# MEC1701Q register map
Vendor: Microchip Technology; Series: MEC1701; File version: 0
CPU: CM4 r1p0, little endian, MPU, FPU, 3 interrupt priority bits
Registers are 32-bit, read-write, reset 0x0 unless marked. A register's access mark holds for its fields unless they carry their own. Offsets are from the block's base; [hi:lo] are bit positions; {n}, {i} and the like mark numbered series; 'fields as' and 'values as' point back to an identical list.

## PM1 — The device implements the ACPI fixed registers but includes only those bits that apply to the power button sleep button and RTC alarm events. The ACPI WAK_STS, SLP_TYP and SLP_EN bits are also supported.
Base 0x400F1C00; register names take the prefix PM1_
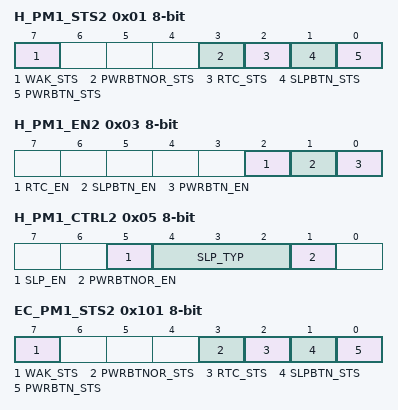
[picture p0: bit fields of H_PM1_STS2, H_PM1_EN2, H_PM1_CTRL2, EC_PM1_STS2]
0x01 H_PM1_STS2 8-bit — PM1 Status 2
  [7] WAK_STS — This bit can be set or cleared by the EC. The Host writing a one to this bit can also clear this bit. (R/WC)
  [3] PWRBTNOR_STS — This bit can be set or cleared by the EC to simulate a Power button override event status if the power is controlled by the EC. The Host writing a one to this bit can also clear this bit. The EC must generate the associated hardware event under software control.(R/WC)
  [2] RTC_STS — This bit can be set or cleared by the EC to simulate a RTC status. The Host writing a one to this bit can also clear this bit. The EC must generate the associated SCI interrupt under software control. (R/WC)
  [1] SLPBTN_STS — This bit can be set or cleared by the EC to simulate a Sleep button status if the sleep state is controlled by the EC. The Host writing a one to this bit can also clear this bit. The EC must generate the associated SCI interrupt under software control.(R/WC)
  [0] PWRBTN_STS — This bit can be set or cleared by the EC to simulate a Power button status if the power is controlled by the EC. The Host writing a one to this bit can also clear this bit. The EC must generate the associated SCI interrupt under software control. (R/WC)
0x03 H_PM1_EN2 8-bit — PM1 Enable 2
  [2] RTC_EN — This bit can be read or written by the Host. It can be read by the EC.
  [1] SLPBTN_EN — This bit can be read or written by the Host. It can be read by the EC.
  [0] PWRBTN_EN — This bit can be read or written by the Host. It can be read by the EC.
0x05 H_PM1_CTRL2 8-bit — PM1 Control 2
  [5] SLP_EN
  [4:2] SLP_TYP — These bits can be set or cleared by the Host, read by the EC.
  [1] PWRBTNOR_EN — This bit can be set or cleared by the Host, read by the EC.
0x101 EC_PM1_STS2 8-bit — PM1 Status 2
  fields as H_PM1_STS2
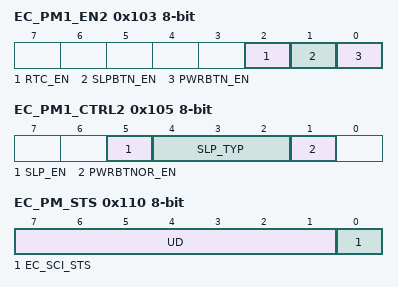
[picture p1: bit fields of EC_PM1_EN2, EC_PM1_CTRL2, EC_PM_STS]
0x103 EC_PM1_EN2 8-bit — PM1 Enable 2
  fields as H_PM1_EN2
0x105 EC_PM1_CTRL2 8-bit — PM1 Control 2
  fields as H_PM1_CTRL2
0x110 EC_PM_STS 8-bit — PM1 EC PM Status
  [7:1] UD — User Defined
  [0] EC_SCI_STS — If the EC_SCI_STS bit is '1', an interrupt is generated on the EC_SCI# pin.

## PS2_0 — There are four PS/2 Ports which are directly controlled by the EC. The hardware implementation eliminates the need to bit bang I/O ports to generate PS/2 traffic, however bit banging is available via the associated GPIO pins.
Base 0x40009000; register names take the prefix PS2_
Same registers: PS2_1 0x40009040, PS2_2 0x40009080
0x00 TX_DATA wo — Writes to bits 7:0 of this register start a transmission of the data in this register to the peripheral
0x00 RX_DATA ro reset 0xFF — Data received from a peripheral are recorded in this register in bits 7:0.
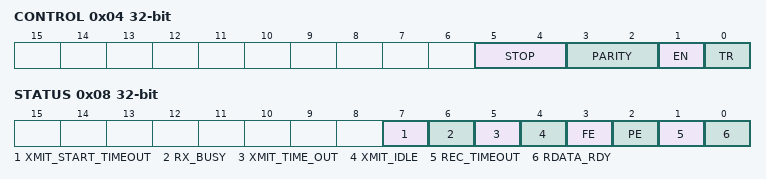
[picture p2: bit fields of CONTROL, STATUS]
0x04 CONTROL — PS2 Control Register
  [5:4] STOP — 00b=Receiver expects an active high stop bit. 01b=Receiver expects an active low stop bit. 10b=Receiver ignores the level of the Stop bit (11th bit is not interpreted as a stop bit). 11b=Reserved.
  [3:2] PARITY — 00b=Receiver expects Odd Parity (default). 01b=Receiver expects Even Parity. 10b=Receiver ignores level of the parity bit (10th bit is not interpreted as a parity bit). 11b=Reserved
  [1] EN — PS/2 Enable. 0=The PS/2 state machine is disabled. 1=The PS/2 state machine is enabled.
  [0] TR — PS/2 Transmit/Receive. 0=The P2/2 channel is enabled to receive data. 1=The PS2 channel is enabled to transmit data.
0x08 STATUS — PS2 Status Register
  [7] XMIT_START_TIMEOUT — Transmit Start Timeout. 0=No transmit start timeout detected. 1=A start bit was not received within 25 ms following the transmit start event. The transmit start bit time-out condition is also indicated by the XMIT_TIMEOUT bit.
  [6] RX_BUSY — Receive Channel Busy. 0=The channel is idle. 1=The channel is actively receiving PS/2 data
  [5] XMIT_TIME_OUT — Transmitter Time-out. When the XMIT_TIMEOUT bit is set, the PS2_T/R bit is held clear, the PS/2 channel's CLK line is pulled low for a minimum of 300us until the PS/2 Status register is read.
  [4] XMIT_IDLE — Transmitter Idle. 0=The channel is actively transmitting PS/2 data. 1=The channel is not transmitting. A low to high transition on this bit generates a PS2 Activity interrupt.
  [3] FE — Framing Error
  [2] PE — Parity Error
  [1] REC_TIMEOUT — Receive Timeout. The REC_TIMEOUT bit is cleared when the Status Register is read. A low to high transition on this bit generates a PS2 Activity interrupt. (R/WC)
  [0] RDATA_RDY — Receive Data Ready. Reading the Receive Register clears this bit. A low to high transition on this bit generates a PS2 Activity interrupt.

## MPU — Memory Protection Unit Registers
Base 0xE000ED90; register names take the prefix MPU_
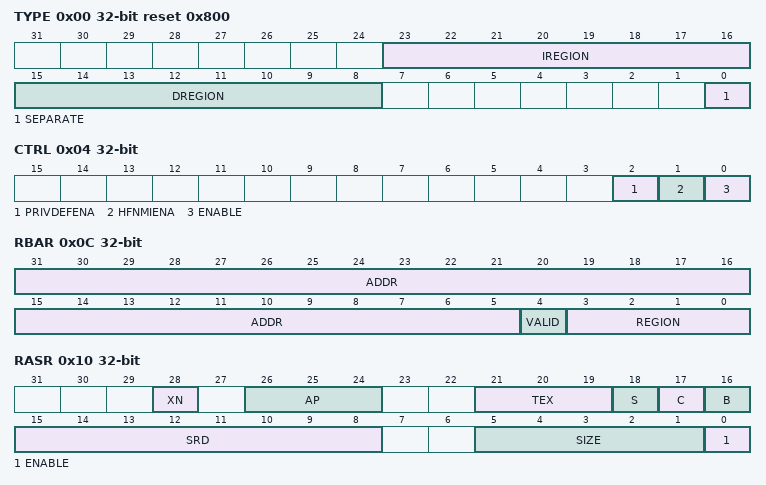
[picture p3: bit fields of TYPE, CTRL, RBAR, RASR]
0x00 TYPE ro reset 0x800 — MPU Type Register
  [23:16] IREGION — Indicates the number of supported MPU data regions.
  [15:8] DREGION — Indicates the number of supported MPU instruction regions.
  [0] SEPARATE — Indicates support for unified or separate instruction and date memory maps.
0x04 CTRL — MPU Control Register
  [2] PRIVDEFENA — Enables privileged software access to the default memory map.
  [1] HFNMIENA — Enables the operation of MPU during hard fault, NMI, and FAULTMASK handlers.
  [0] ENABLE — Enables the MPU
0x08 RNR — MPU Region Number Register
  [7:0] REGION — Indicates the MPU region referenced by the MPU_RBAR and MPU_RASR registers.
0x0C RBAR — MPU Region Base Address Register
  [31:5] ADDR — Region base address field.
  [4] VALID — MPU Region Number valid bit.
  [3:0] REGION — MPU region field.
0x10 RASR — MPU Region Attribute and Size Register
  [28] XN — Instruction access disable bit.
  [26:24] AP — Access permission field.
  [21:19] TEX — MPU access permission attributes.
  [18] S — Shareable bit.
  [17] C — MPU access permission attributes.
  [16] B — MPU access permission attributes.
  [15:8] SRD — Subregion disable bits.
  [5:1] SIZE — Specifies the size of the MPU protection region.
  [0] ENABLE — Region enable bit.

## NVIC — Nested Vectored Interrupt Controller
Base 0xE000E100; register names take the prefix NVIC_
{0x0+4i} ISER[{i}] (i=0..0) — Interrupt Set Enable Register
  [31:0] SETENA — Interrupt set enable bits
{0x80+4i} ICER[{i}] (i=0..0) — Interrupt Clear Enable Register
  [31:0] CLRENA — Interrupt clear-enable bits
{0x100+4i} ISPR[{i}] (i=0..0) — Interrupt Set Pending Register
  [31:0] SETPEND — Interrupt set-pending bits
{0x180+4i} ICPR[{i}] (i=0..0) — Interrupt Clear Pending Register
  [31:0] CLRPEND — Interrupt clear-pending bits
{0x200+4i} IABR[{i}] (i=0..0) — Interrupt Active Bit Register
  [31:0] ACTIVE — Interrupt active bits
{0x300+i} IP[{i}] (i=0..7) 8-bit — Interrupt Priority Register n
  [2:0] PRI0 — Priority of interrupt n
0xE00 STIR wo — Software Trigger Interrupt Register
  [8:0] INTID — Interrupt ID to trigger

## SysTick — System timer
Base 0xE000E010; register names take the prefix SysTick_
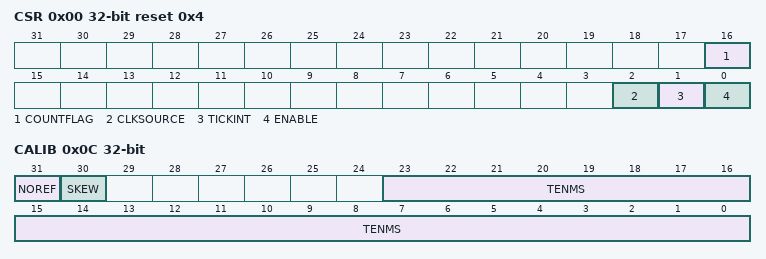
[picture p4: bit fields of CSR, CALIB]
0x00 CSR reset 0x4 — SysTick Control and Status Register
  [16] COUNTFLAG — Timer counted to 0 since last read of register
  [2] CLKSOURCE — Clock Source 0=external, 1=processor
    0=External clock; 1=Processor clock
  [1] TICKINT — SysTick Exception Request Enable
    0=Counting down to 0 does not assert the SysTick exception request; 1=Counting down to 0 asserts the SysTick exception request
  [0] ENABLE — SysTick Counter Enable
    0=Counter disabled; 1=Counter enabled
0x04 RVR — SysTick Reload Value Register
  [23:0] RELOAD — Value to load into the SysTick Current Value Register when the counter reaches 0
0x08 CVR — SysTick Current Value Register
  [23:0] CURRENT — Current value at the time the register is accessed
0x0C CALIB ro — SysTick Calibration Value Register
  [31] NOREF — No Separate Reference Clock
    0=The reference clock is provided; 1=The reference clock is not provided
  [30] SKEW — TENMS is rounded from non-integer ratio
    0=10ms calibration value is exact; 1=10ms calibration value is inexact, because of the clock frequency
  [23:0] TENMS — Reload value to use for 10ms timing
